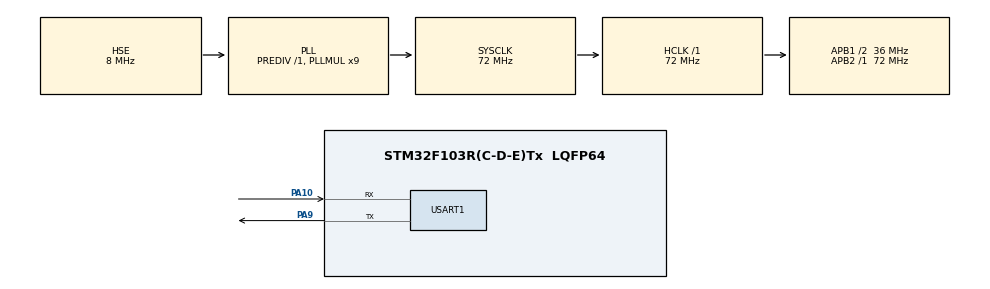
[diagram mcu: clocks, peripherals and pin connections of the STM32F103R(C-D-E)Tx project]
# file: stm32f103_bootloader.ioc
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Mcu.Family=STM32F1
Mcu.Name=STM32F103R(C-D-E)Tx
Mcu.Package=LQFP64
NVIC.PriorityGroup=NVIC_PRIORITYGROUP_4
PA10.Mode=Asynchronous
PA10.Signal=USART1_RX
PA13.Mode=Serial_Wire
PA13.Signal=SYS_JTMS-SWDIO
PA14.Mode=Serial_Wire
PA14.Signal=SYS_JTCK-SWCLK
PA9.Mode=Asynchronous
PA9.Signal=USART1_TX
PC14-OSC32_IN.Mode=LSE-External-Oscillator
PC14-OSC32_IN.Signal=RCC_OSC32_IN
PC15-OSC32_OUT.Mode=LSE-External-Oscillator
PC15-OSC32_OUT.Signal=RCC_OSC32_OUT
PD0-OSC_IN.Mode=HSE-External-Oscillator
PD0-OSC_IN.Signal=RCC_OSC_IN
PD1-OSC_OUT.Mode=HSE-External-Oscillator
PD1-OSC_OUT.Signal=RCC_OSC_OUT
ProjectManager.HeapSize=0x200
ProjectManager.StackSize=0x400
ProjectManager.TargetToolchain=MDK-ARM V5.32
RCC.AHBFreq_Value=72000000
RCC.APB1CLKDivider=RCC_HCLK_DIV2
RCC.APB1Freq_Value=36000000
RCC.APB1TimFreq_Value=72000000
RCC.APB2Freq_Value=72000000
RCC.APB2TimFreq_Value=72000000
RCC.HCLKFreq_Value=72000000
RCC.PLLMUL=RCC_PLL_MUL9
RCC.PLLSourceVirtual=RCC_PLLSOURCE_HSE
RCC.SYSCLKFreq_VALUE=72000000
RCC.SYSCLKSource=RCC_SYSCLKSOURCE_PLLCLK
RCC.USBFreq_Value=72000000
USART1.VirtualMode=VM_ASYNC
board=custom

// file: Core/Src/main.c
/* USER CODE BEGIN Header */
/**
  ******************************************************************************
  * @file           : main.c
  * @brief          : Main program body
  ******************************************************************************
  * @attention
  *
  * <h2><center>&copy; Copyright (c) 2022 STMicroelectronics.
  * All rights reserved.</center></h2>
  *
  * This software component is licensed by ST under BSD 3-Clause license,
  * the "License"; You may not use this file except in compliance with the
  * License. You may obtain a copy of the License at:
  *                        opensource.org/licenses/BSD-3-Clause
  *
  ******************************************************************************
  */
/* USER CODE END Header */
#include "main.h"
#include "usart.h"
#include "gpio.h"

/* USER CODE BEGIN Includes */
#include "iap.h"
#include "stmflash.h"
/* USER CODE END Includes */

void SystemClock_Config(void);

/* USER CODE BEGIN 0 */
uint8_t   FlashBuf[12] = {0};
uint32_t  UpgreadeSign = 0;
uint32_t  Chk_Sum = 0;
uint32_t  Bin_Lengths = 0;
uint8_t   ar_resetcont_buff[1] = {0x00};
/* USER CODE END 0 */

int main(void)
{

  /* MCU Configuration--------------------------------------------------------*/

  /* Reset of all peripherals, Initializes the Flash interface and the Systick. */
  HAL_Init();

  /* Configure the system clock */
  SystemClock_Config();

  /* Initialize all configured peripherals */
  MX_GPIO_Init();
  MX_USART1_UART_Init();
  /* USER CODE BEGIN 2 */
	printf("boootloder runing\n");

	STMFLASH_ReadNByte(UPDATA_BACKC_ADDRESS,FlashBuf,12);
	memcpy((uint8_t*)&UpgreadeSign,FlashBuf,4);
	memcpy((uint8_t*)&Chk_Sum,&FlashBuf[4],4);
	memcpy((uint8_t*)&Bin_Lengths,&FlashBuf[8],4);

	STMFLASH_ReadNByte(UPDATA_BACKD_ADDRESS,ar_resetcont_buff,1);
	ar_resetcont_buff[0]=ar_resetcont_buff[0]+1;
	STMFLASH_EraseSec(UPDATA_BACKD_ADDRESS,(UPDATA_BACKD_ADDRESS+FLASH_PAGE_SIZE));
	STMFLASH_Write_HalfWord(UPDATA_BACKD_ADDRESS,(uint16_t*)ar_resetcont_buff, 1);
	STMFLASH_ReadNByte(UPDATA_BACKD_ADDRESS,ar_resetcont_buff,1);
	printf("reset times =%d \n",ar_resetcont_buff[0]);

	if(ar_resetcont_buff[0]==0)
  {
			copy_app_to_datab_addr();
	}

	if(UpgreadeSign == 0x55555555) //升级标志置位了，则将升级区的代码拷贝到应用区，断电重启后
	{
		  printf("need updata firmware\n");
		  copy_dataa_to_app_addr(Bin_Lengths);
		  STMFLASH_EraseSec(UPDATA_BACKC_ADDRESS,(UPDATA_BACKC_ADDRESS+FLASH_PAGE_SIZE));  //擦除扇区7  将标志位清除
	}

	if(ar_resetcont_buff[0]>3)  //接收的待升级固件不能跳转回退到上一版本
  {
		  printf("back before app\n");
      copy_datab_to_app_addr();
	}

  iap_load_app(APP_START_ADDRESS);
  /* USER CODE END 2 */

  /* Infinite loop */
  while (1)
  {

    /* USER CODE BEGIN 3 */
		printf("boootloder looping\r\n");
		HAL_Delay(100);
  }
  /* USER CODE END 3 */
}

void SystemClock_Config(void)
{
  RCC_OscInitTypeDef RCC_OscInitStruct = {0};
  RCC_ClkInitTypeDef RCC_ClkInitStruct = {0};

  /** Initializes the RCC Oscillators according to the specified parameters
  * in the RCC_OscInitTypeDef structure.
  */
  RCC_OscInitStruct.OscillatorType = RCC_OSCILLATORTYPE_HSE;
  RCC_OscInitStruct.HSEState = RCC_HSE_ON;
  RCC_OscInitStruct.HSEPredivValue = RCC_HSE_PREDIV_DIV1;
  RCC_OscInitStruct.HSIState = RCC_HSI_ON;
  RCC_OscInitStruct.PLL.PLLState = RCC_PLL_ON;
  RCC_OscInitStruct.PLL.PLLSource = RCC_PLLSOURCE_HSE;
  RCC_OscInitStruct.PLL.PLLMUL = RCC_PLL_MUL9;
  if (HAL_RCC_OscConfig(&RCC_OscInitStruct) != HAL_OK)
  {
    Error_Handler();
  }
  /** Initializes the CPU, AHB and APB buses clocks
  */
  RCC_ClkInitStruct.ClockType = RCC_CLOCKTYPE_HCLK|RCC_CLOCKTYPE_SYSCLK
                              |RCC_CLOCKTYPE_PCLK1|RCC_CLOCKTYPE_PCLK2;
  RCC_ClkInitStruct.SYSCLKSource = RCC_SYSCLKSOURCE_PLLCLK;
  RCC_ClkInitStruct.AHBCLKDivider = RCC_SYSCLK_DIV1;
  RCC_ClkInitStruct.APB1CLKDivider = RCC_HCLK_DIV2;
  RCC_ClkInitStruct.APB2CLKDivider = RCC_HCLK_DIV1;

  if (HAL_RCC_ClockConfig(&RCC_ClkInitStruct, FLASH_LATENCY_2) != HAL_OK)
  {
    Error_Handler();
  }
}

void Error_Handler(void)
{
  __disable_irq();
  while (1)
  {
  }
}

/************************ (C) COPYRIGHT STMicroelectronics *****END OF FILE****/
